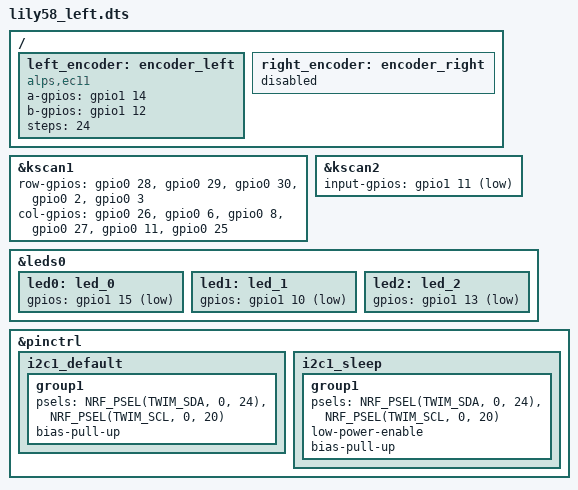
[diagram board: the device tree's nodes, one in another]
#include "lily58.dtsi"

/ {
    left_encoder: encoder_left {
        compatible = "alps,ec11";
        a-gpios = <&gpio1 14 (GPIO_ACTIVE_HIGH | GPIO_PULL_UP)>;
        b-gpios = <&gpio1 12 (GPIO_ACTIVE_HIGH | GPIO_PULL_UP)>;
        steps = <24>;
    };

    right_encoder: encoder_right {
        status = "disabled";
    };

};

&kscan1 {
    row-gpios
        = <&gpio0 28 (GPIO_ACTIVE_HIGH | GPIO_PULL_DOWN)>
        , <&gpio0 29 (GPIO_ACTIVE_HIGH | GPIO_PULL_DOWN)>
        , <&gpio0 30 (GPIO_ACTIVE_HIGH | GPIO_PULL_DOWN)>
        , <&gpio0 2 (GPIO_ACTIVE_HIGH | GPIO_PULL_DOWN)>
        , <&gpio0 3 (GPIO_ACTIVE_HIGH | GPIO_PULL_DOWN)>
        ;

    col-gpios
        = <&gpio0 26 GPIO_ACTIVE_HIGH>
        , <&gpio0 6 GPIO_ACTIVE_HIGH>
        , <&gpio0 8 GPIO_ACTIVE_HIGH>
        , <&gpio0 27 GPIO_ACTIVE_HIGH>
        , <&gpio0 11 GPIO_ACTIVE_HIGH>
        , <&gpio0 25 GPIO_ACTIVE_HIGH>
        ;
};

&kscan2 {
        input-gpios
            = <&gpio1 11 (GPIO_ACTIVE_LOW | GPIO_PULL_UP)>
            ;
};

&leds0 {
    led0: led_0 {
        gpios = <&gpio1 15 GPIO_ACTIVE_LOW>;  // red LED
    };
    led1: led_1 {
        gpios = <&gpio1 10 GPIO_ACTIVE_LOW>;  // green LED
    };
    led2: led_2 {
        gpios = <&gpio1 13 GPIO_ACTIVE_LOW>;  // blue LED
    };
};

&pinctrl {
    i2c1_default: i2c1_default {
        group1 {
            psels = <NRF_PSEL(TWIM_SDA, 0, 24)>,
                    <NRF_PSEL(TWIM_SCL, 0, 20)>;
            bias-pull-up;
        };
    };

    i2c1_sleep: i2c1_sleep {
        group1 {
            psels = <NRF_PSEL(TWIM_SDA, 0, 24)>,
                    <NRF_PSEL(TWIM_SCL, 0, 20)>;
            low-power-enable;
            bias-pull-up;
        };
    };
};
